AUTOSAR XML (schema 4.0)
package /Components
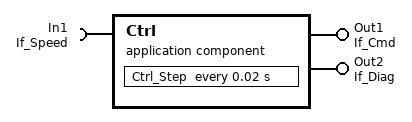
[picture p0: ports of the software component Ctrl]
  application sw component type Ctrl
    require port In1: required-interface=If_Speed
    provide port Out1: provided-interface=If_Cmd
    provide port Out2: provided-interface=If_Diag
    behavior IB
      timing event TE_Step: start-on-event=Ctrl_Step, period=0.02
      runnable Ctrl_Step
